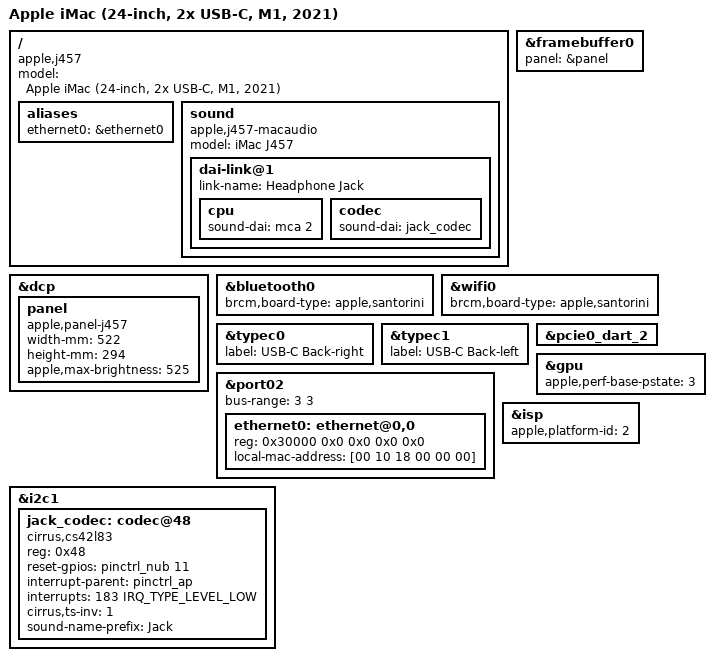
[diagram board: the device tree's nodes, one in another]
// SPDX-License-Identifier: GPL-2.0+ OR MIT
/*
 * Apple iMac (24-inch, 2x USB-C, M1, 2020)
 *
 * target-type: J457
 *
 * Copyright The Asahi Linux Contributors
 */

/dts-v1/;

#include "t8103.dtsi"
#include "t8103-jxxx.dtsi"

/ {
	compatible = "apple,j457", "apple,t8103", "apple,arm-platform";
	model = "Apple iMac (24-inch, 2x USB-C, M1, 2021)";

	aliases {
		ethernet0 = &ethernet0;
	};
};

&dcp {
	panel: panel {
		compatible = "apple,panel-j457", "apple,panel";
		width-mm = <522>;
		height-mm = <294>;
		apple,max-brightness = <525>;
	};
};

&framebuffer0 {
	panel = &panel;
};

&bluetooth0 {
	brcm,board-type = "apple,santorini";
};

&wifi0 {
	brcm,board-type = "apple,santorini";
};

/*
 * Provide labels for the USB type C ports.
 */

&typec0 {
	label = "USB-C Back-right";
};

&typec1 {
	label = "USB-C Back-left";
};

/*
 * Force the bus number assignments so that we can declare some of the
 * on-board devices and properties that are populated by the bootloader
 * (such as MAC addresses).
 */

&port02 {
	bus-range = <3 3>;
	status = "okay";
	ethernet0: ethernet@0,0 {
		reg = <0x30000 0x0 0x0 0x0 0x0>;
		/* To be filled by the loader */
		local-mac-address = [00 10 18 00 00 00];
	};
};

&pcie0_dart_2 {
	status = "okay";
};

&i2c1 {
	jack_codec: codec@48 {
		compatible = "cirrus,cs42l83";
		reg = <0x48>;
		reset-gpios = <&pinctrl_nub 11 GPIO_ACTIVE_HIGH>;
		interrupt-parent = <&pinctrl_ap>;
		interrupts = <183 IRQ_TYPE_LEVEL_LOW>;
		#sound-dai-cells = <0>;
		cirrus,ts-inv = <1>;
		sound-name-prefix = "Jack";
	};
};

/ {
	sound {
		compatible = "apple,j457-macaudio", "apple,macaudio";
		model = "iMac J457";

		dai-link@1 {
			link-name = "Headphone Jack";

			cpu {
				sound-dai = <&mca 2>;
			};
			codec {
				sound-dai = <&jack_codec>;
			};
		};
	};
};

&gpu {
	apple,perf-base-pstate = <3>;
};

#include "isp-imx364.dtsi"

&isp {
	apple,platform-id = <2>;
};

#include "hwmon-fan.dtsi"
